# STM32G484xx register map
File version: 1.0
Registers are 32-bit, read-write, reset 0x0 unless marked. A register's access mark holds for its fields unless they carry their own. Offsets are from the block's base; [hi:lo] are bit positions; {n}, {i} and the like mark numbered series; 'fields as' and 'values as' point back to an identical list.

## RCC — Reset and Clock Control
Base 0x40021000
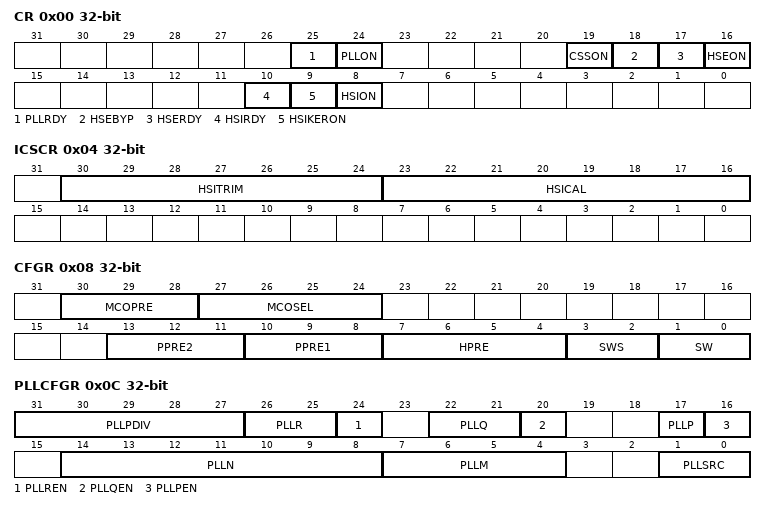
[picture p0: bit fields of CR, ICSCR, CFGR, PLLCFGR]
0x00 CR — RCC clock control register
  [25] PLLRDY — System PLL clock ready
  [24] PLLON — System PLL clock enable
  [19] CSSON — HSE Clock Security System enable
  [18] HSEBYP — External High Speed oscillator (HSE) clock bypass
  [17] HSERDY — External High Speed oscillator (HSE) clock ready
  [16] HSEON — External High Speed oscillator (HSE) clock enable
  [10] HSIRDY — Internal High Speed oscillator (HSI16) clock ready flag
  [9] HSIKERON — Internal High Speed oscillator (HSI16) clock enable for some IPs Kernel
  [8] HSION — Internal High Speed oscillator (HSI16) clock enable
0x04 ICSCR — RCC internal clock sources calibration register
  [30:24] HSITRIM — HSITRIM[6:0] bits
  [23:16] HSICAL — HSICAL[7:0] bits
0x08 CFGR — RCC clock configuration register
  [30:28] MCOPRE — MCO prescaler
  [27:24] MCOSEL — MCOSEL [3:0] bits (Clock output selection)
  [13:11] PPRE2 — PRE2[2:0] bits (APB2 prescaler)
    0=DIV_1 (HCLK not divided); 4=DIV_2 (HCLK divided by 2); 5=DIV_4 (HCLK divided by 4); 6=DIV_8 (HCLK divided by 8); 7=DIV_16 (HCLK divided by 16)
  [10:8] PPRE1 — PRE1[2:0] bits (APB2 prescaler)
    values as PPRE2
  [7:4] HPRE — HPRE[3:0] bits (AHB prescaler)
    0=DIV_1 (SYSCLK not divided); 8=DIV_2 (SYSCLK divided by 2); 9=DIV_4 (SYSCLK divided by 4); 10=DIV_8 (SYSCLK divided by 8); 11=DIV_16 (SYSCLK divided by 16); 12=DIV_64 (SYSCLK divided by 64); 13=DIV_128 (SYSCLK divided by 128); 14=DIV_256 (SYSCLK divided by 256); 15=DIV_512 (SYSCLK divided by 512)
  [3:2] SWS — SWS[1:0] bits (System Clock Switch Status)
    1=HSI (HSI used as system clock); 2=HSE (HSE used as system clock); 3=PLL (PLL used as system clock)
  [1:0] SW — SW[1:0] bits (System clock Switch)
    1=HSI (HSI selection as system clock); 2=HSE (HSE selection as system clock); 3=PLL (PLL selection as system clock)
0x0C PLLCFGR — RCC system PLL configuration register
  [31:27] PLLPDIV
  [26:25] PLLR
    0=DIV_2 (Main PLL division factor for PLLCLK (system clock) by 2); 1=DIV_4 (Main PLL division factor for PLLCLK (system clock) by 4); 2=DIV_6 (Main PLL division factor for PLLCLK (system clock) by 6); 3=DIV_8 (Main PLL division factor for PLLCLK (system clock) by 8)
  [24] PLLREN
  [22:21] PLLQ
    0=DIV_2 (Main PLL division factor for PLLQ output by 2); 1=DIV_4 (Main PLL division factor for PLLQ output by 4); 2=DIV_6 (Main PLL division factor for PLLQ output by 6); 3=DIV_8 (Main PLL division factor for PLLQ output by 8)
  [20] PLLQEN
  [17] PLLP
  [16] PLLPEN
  [14:8] PLLN
  [7:4] PLLM
    {v}=DIV_{v+1} (PLL division factor by {v+1}) (v=0..15)
  [1:0] PLLSRC
    0=NONE (No clock); 2=HSI (HSI16 clock selected as PLL entry clock source); 3=HSE (HSE clock selected as PLL entry clock source)
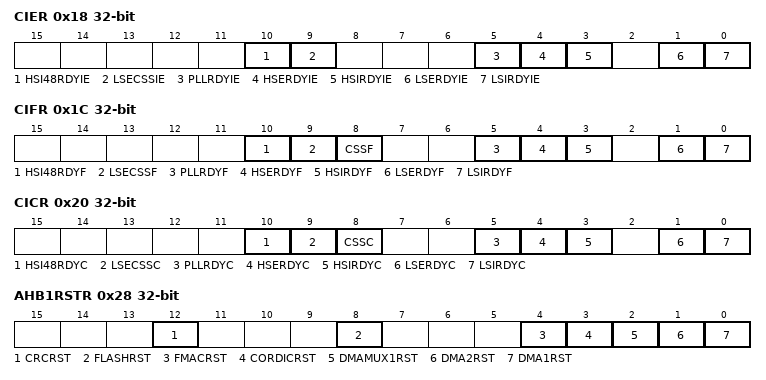
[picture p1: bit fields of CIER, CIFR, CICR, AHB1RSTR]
0x18 CIER — RCC clock interrupt enable register
  [10] HSI48RDYIE, [9] LSECSSIE, [5] PLLRDYIE, [4] HSERDYIE, [3] HSIRDYIE, [1] LSERDYIE, [0] LSIRDYIE
0x1C CIFR — RCC clock interrupt flag register
  [10] HSI48RDYF, [9] LSECSSF, [8] CSSF, [5] PLLRDYF, [4] HSERDYF, [3] HSIRDYF, [1] LSERDYF, [0] LSIRDYF
0x20 CICR — RCC clock interrupt clear register
  [10] HSI48RDYC, [9] LSECSSC, [8] CSSC, [5] PLLRDYC, [4] HSERDYC, [3] HSIRDYC, [1] LSERDYC, [0] LSIRDYC
0x28 AHB1RSTR — RCC AHB1 peripheral reset register
  [12] CRCRST, [8] FLASHRST, [4] FMACRST, [3] CORDICRST, [2] DMAMUX1RST, [1] DMA2RST, [0] DMA1RST
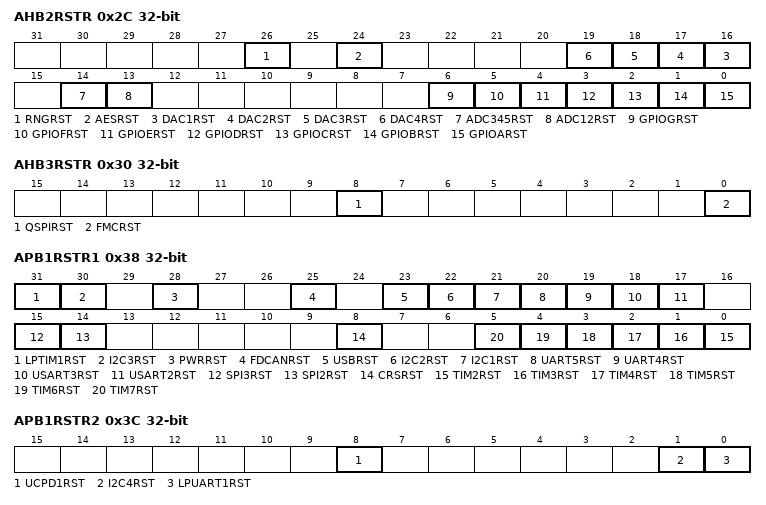
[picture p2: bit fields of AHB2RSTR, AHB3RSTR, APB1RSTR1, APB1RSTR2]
0x2C AHB2RSTR — RCC AHB2 peripheral reset register
  [26] RNGRST, [24] AESRST, [n+15] DAC{n}RST (n=1..4), [14] ADC345RST, [13] ADC12RST, [6] GPIOGRST, [5] GPIOFRST, [4] GPIOERST, [3] GPIODRST, [2] GPIOCRST, [1] GPIOBRST, [0] GPIOARST
0x30 AHB3RSTR — RCC AHB3 peripheral reset register
  [8] QSPIRST, [0] FMCRST
0x38 APB1RSTR1 — RCC APB1 peripheral reset register 1
  [31] LPTIM1RST, [30] I2C3RST, [28] PWRRST, [25] FDCANRST, [23] USBRST, [22] I2C2RST, [21] I2C1RST, [20] UART5RST, [19] UART4RST, [18] USART3RST, [17] USART2RST, [15] SPI3RST, [14] SPI2RST, [8] CRSRST, [n-2] TIM{n}RST (n=2..7)
0x3C APB1RSTR2 — RCC APB1 peripheral reset register 2
  [8] UCPD1RST, [1] I2C4RST, [0] LPUART1RST
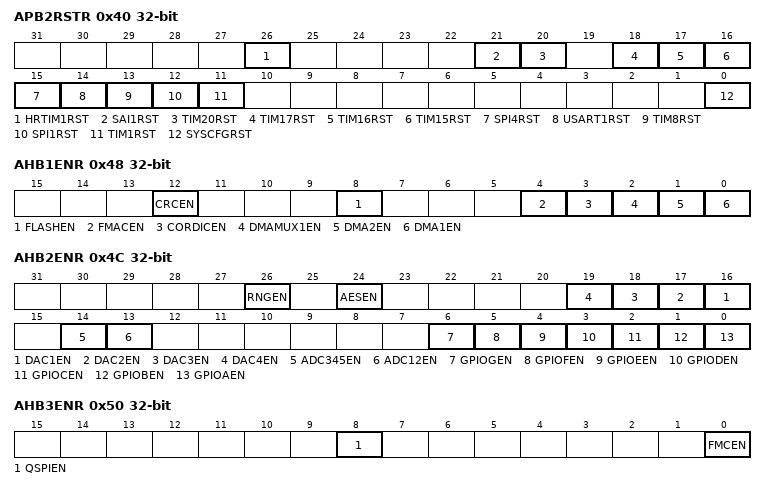
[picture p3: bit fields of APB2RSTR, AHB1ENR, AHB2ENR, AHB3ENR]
0x40 APB2RSTR — RCC APB2 peripheral reset register
  [26] HRTIM1RST, [21] SAI1RST, [20] TIM20RST, [18] TIM17RST, [17] TIM16RST, [16] TIM15RST, [15] SPI4RST, [14] USART1RST, [13] TIM8RST, [12] SPI1RST, [11] TIM1RST, [0] SYSCFGRST
0x48 AHB1ENR — RCC AHB1 peripheral clocks enable register
  [12] CRCEN, [8] FLASHEN, [4] FMACEN, [3] CORDICEN, [2] DMAMUX1EN, [1] DMA2EN, [0] DMA1EN
0x4C AHB2ENR — RCC AHB2 peripheral clocks enable register
  [26] RNGEN, [24] AESEN, [n+15] DAC{n}EN (n=1..4), [14] ADC345EN, [13] ADC12EN, [6] GPIOGEN, [5] GPIOFEN, [4] GPIOEEN, [3] GPIODEN, [2] GPIOCEN, [1] GPIOBEN, [0] GPIOAEN
0x50 AHB3ENR — RCC AHB3 peripheral clocks enable register
  [8] QSPIEN, [0] FMCEN
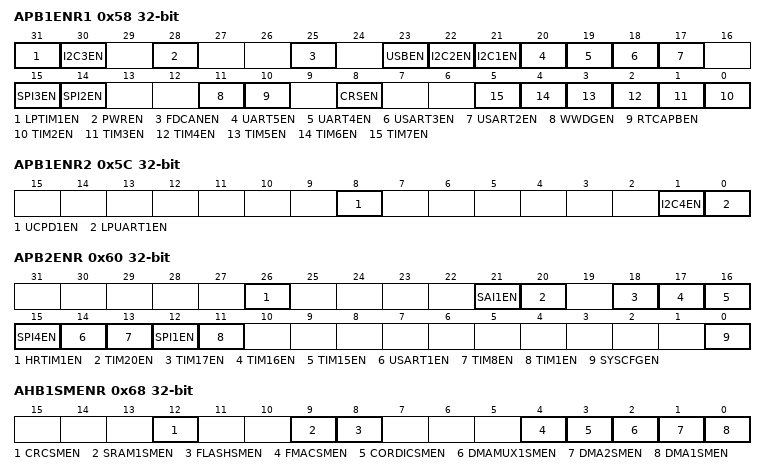
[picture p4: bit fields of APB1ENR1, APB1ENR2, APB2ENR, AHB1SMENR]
0x58 APB1ENR1 — RCC APB1 peripheral clocks enable register 1
  [31] LPTIM1EN, [30] I2C3EN, [28] PWREN, [25] FDCANEN, [23] USBEN, [22] I2C2EN, [21] I2C1EN, [20] UART5EN, [19] UART4EN, [18] USART3EN, [17] USART2EN, [15] SPI3EN, [14] SPI2EN, [11] WWDGEN, [10] RTCAPBEN, [8] CRSEN, [n-2] TIM{n}EN (n=2..7)
0x5C APB1ENR2 — RCC APB1 peripheral clocks enable register 2
  [8] UCPD1EN, [1] I2C4EN, [0] LPUART1EN
0x60 APB2ENR — RCC APB2 peripheral clocks enable register
  [26] HRTIM1EN, [21] SAI1EN, [20] TIM20EN, [18] TIM17EN, [17] TIM16EN, [16] TIM15EN, [15] SPI4EN, [14] USART1EN, [13] TIM8EN, [12] SPI1EN, [11] TIM1EN, [0] SYSCFGEN
0x68 AHB1SMENR — RCC AHB1 peripheral clocks enable in sleep and stop modes register
  [12] CRCSMEN, [9] SRAM1SMEN, [8] FLASHSMEN, [4] FMACSMEN, [3] CORDICSMEN, [2] DMAMUX1SMEN, [1] DMA2SMEN, [0] DMA1SMEN
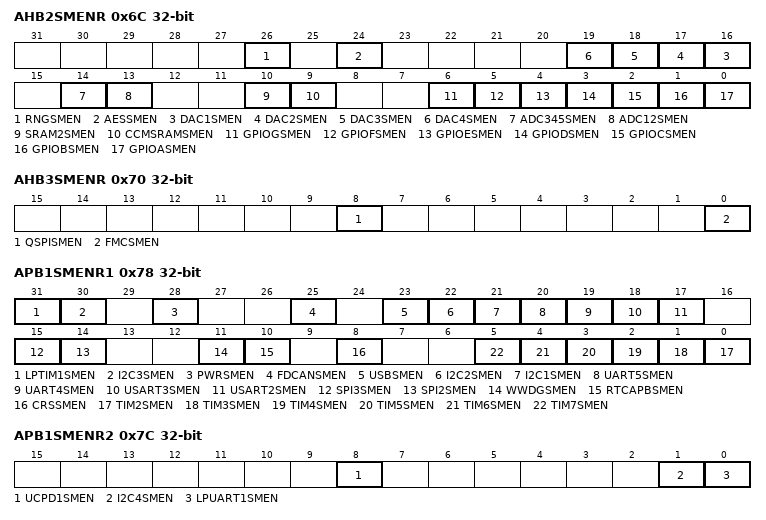
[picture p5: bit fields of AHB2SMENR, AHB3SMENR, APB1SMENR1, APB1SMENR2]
0x6C AHB2SMENR — RCC AHB2 peripheral clocks enable in sleep and stop modes register
  [26] RNGSMEN, [24] AESSMEN, [n+15] DAC{n}SMEN (n=1..4), [14] ADC345SMEN, [13] ADC12SMEN, [10] SRAM2SMEN, [9] CCMSRAMSMEN, [6] GPIOGSMEN, [5] GPIOFSMEN, [4] GPIOESMEN, [3] GPIODSMEN, [2] GPIOCSMEN, [1] GPIOBSMEN, [0] GPIOASMEN
0x70 AHB3SMENR — RCC AHB3 peripheral clocks enable in sleep and stop modes register
  [8] QSPISMEN, [0] FMCSMEN
0x78 APB1SMENR1 — RCC APB1 peripheral clocks enable in sleep mode and stop modes register 1
  [31] LPTIM1SMEN, [30] I2C3SMEN, [28] PWRSMEN, [25] FDCANSMEN, [23] USBSMEN, [22] I2C2SMEN, [21] I2C1SMEN, [20] UART5SMEN, [19] UART4SMEN, [18] USART3SMEN, [17] USART2SMEN, [15] SPI3SMEN, [14] SPI2SMEN, [11] WWDGSMEN, [10] RTCAPBSMEN, [8] CRSSMEN, [n-2] TIM{n}SMEN (n=2..7)
0x7C APB1SMENR2 — RCC APB1 peripheral clocks enable in sleep mode and stop modes register 2
  [8] UCPD1SMEN, [1] I2C4SMEN, [0] LPUART1SMEN
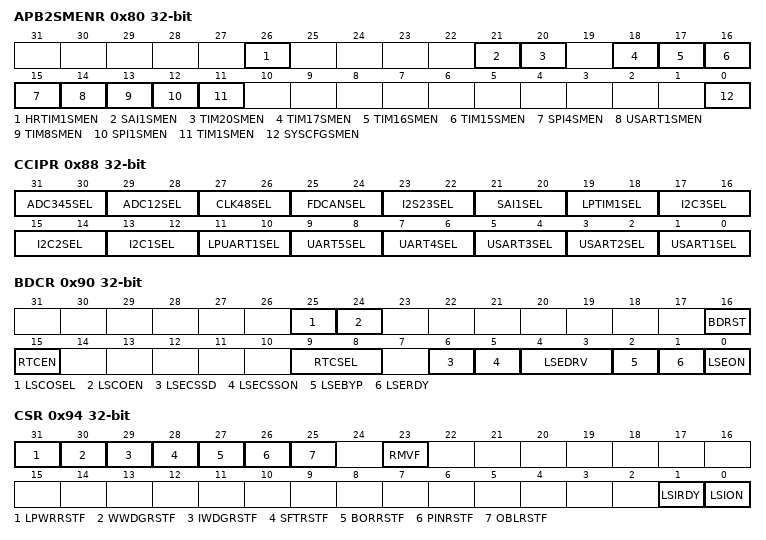
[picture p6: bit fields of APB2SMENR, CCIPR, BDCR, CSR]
0x80 APB2SMENR — RCC APB2 peripheral clocks enable in sleep mode and stop modes register
  [26] HRTIM1SMEN, [21] SAI1SMEN, [20] TIM20SMEN, [18] TIM17SMEN, [17] TIM16SMEN, [16] TIM15SMEN, [15] SPI4SMEN, [14] USART1SMEN, [13] TIM8SMEN, [12] SPI1SMEN, [11] TIM1SMEN, [0] SYSCFGSMEN
0x88 CCIPR — RCC peripherals independent clock configuration register
  [31:30] ADC345SEL
  [29:28] ADC12SEL
  [27:26] CLK48SEL
    0=HSI48 (HSI48 clock used as RNG clock source); 2=PLL (PLL clock used as RNG clock source)
  [25:24] FDCANSEL
    0=HSE (HSE clock used as FDCAN clock source); 1=PLL (PLL clock used as FDCAN clock source); 2=PCLK1 (PCLK1 clock used as FDCAN clock source)
  [23:22] I2S23SEL
    0=SYSCLK (System clock used as I2S clock source); 1=PLL (PLL clock used as I2S clock source); 2=PIN (EXT clock used as I2S clock source); 3=HSI (HSI clock used as I2S clock source)
  [21:20] SAI1SEL
    0=SYSCLK (System clock used as SAI1 clock source); 1=PLL (PLL clock used as SAI1 clock source); 2=PIN (EXT clock used as SAI1 clock source); 3=HSI (HSI clock used as SAI1 clock source)
  [19:18] LPTIM1SEL
    0=PCLK1 (PCLK1 clock used as LPTIM1 clock source); 1=LSI (LSI clock used as LPTIM1 clock source); 2=HSI (HSI clock used as LPTIM1 clock source); 3=LSE (LSE clock used as LPTIM1 clock source)
  [17:16] I2C3SEL
  [15:14] I2C2SEL
  [13:12] I2C1SEL
  [11:10] LPUART1SEL
    0=PCLK1 (PCLK1 clock used as LPUART1 clock source); 1=SYSCLK (SYSCLK clock used as LPUART1 clock source); 2=HSI (HSI clock used as LPUART1 clock source); 3=LSE (LSE clock used as LPUART1 clock source)
  [9:8] UART5SEL
  [7:6] UART4SEL
  [5:4] USART3SEL
  [3:2] USART2SEL
  [1:0] USART1SEL
0x90 BDCR — RCC backup domain control register
  [25] LSCOSEL
    0=LSI (LSI selection for low speed clock); 1=LSE (LSE selection for low speed clock)
  [24] LSCOEN
  [16] BDRST
  [15] RTCEN
  [9:8] RTCSEL
    0=NONE (No clock used as RTC clock); 1=LSE (LSE oscillator clock used as RTC clock); 2=LSI (LSI oscillator clock used as RTC clock); 3=HSE_DIV32 (HSE oscillator clock divided by 32 used as RTC clock)
  [6] LSECSSD
  [5] LSECSSON
  [4:3] LSEDRV
    0=LOW (Xtal mode lower driving capability); 1=MEDIUMLOW (Xtal mode medium low driving capability); 2=MEDIUMHIGH (Xtal mode medium high driving capability); 3=HIGH (Xtal mode higher driving capability)
  [2] LSEBYP
  [1] LSERDY
  [0] LSEON
0x94 CSR — RCC clock control & status register
  [31] LPWRRSTF, [30] WWDGRSTF, [29] IWDGRSTF, [28] SFTRSTF, [27] BORRSTF, [26] PINRSTF, [25] OBLRSTF, [23] RMVF, [1] LSIRDY, [0] LSION
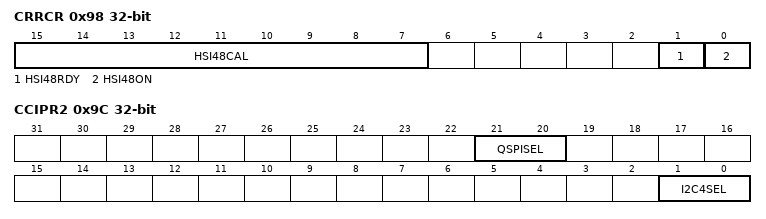
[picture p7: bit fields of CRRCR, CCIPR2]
0x98 CRRCR — RCC clock recovery RC register
  [15:7] HSI48CAL — HSI48CAL[8:0] bits
  [1] HSI48RDY
  [0] HSI48ON
0x9C CCIPR2 — RCC peripherals independent clock configuration register 2
  [21:20] QSPISEL
    0=SYSCLK (SYSCLK used as QuadSPI clock source); 1=HSI (HSI used as QuadSPI clock source); 2=PLL (PLL used as QuadSPI clock source)
  [1:0] I2C4SEL
